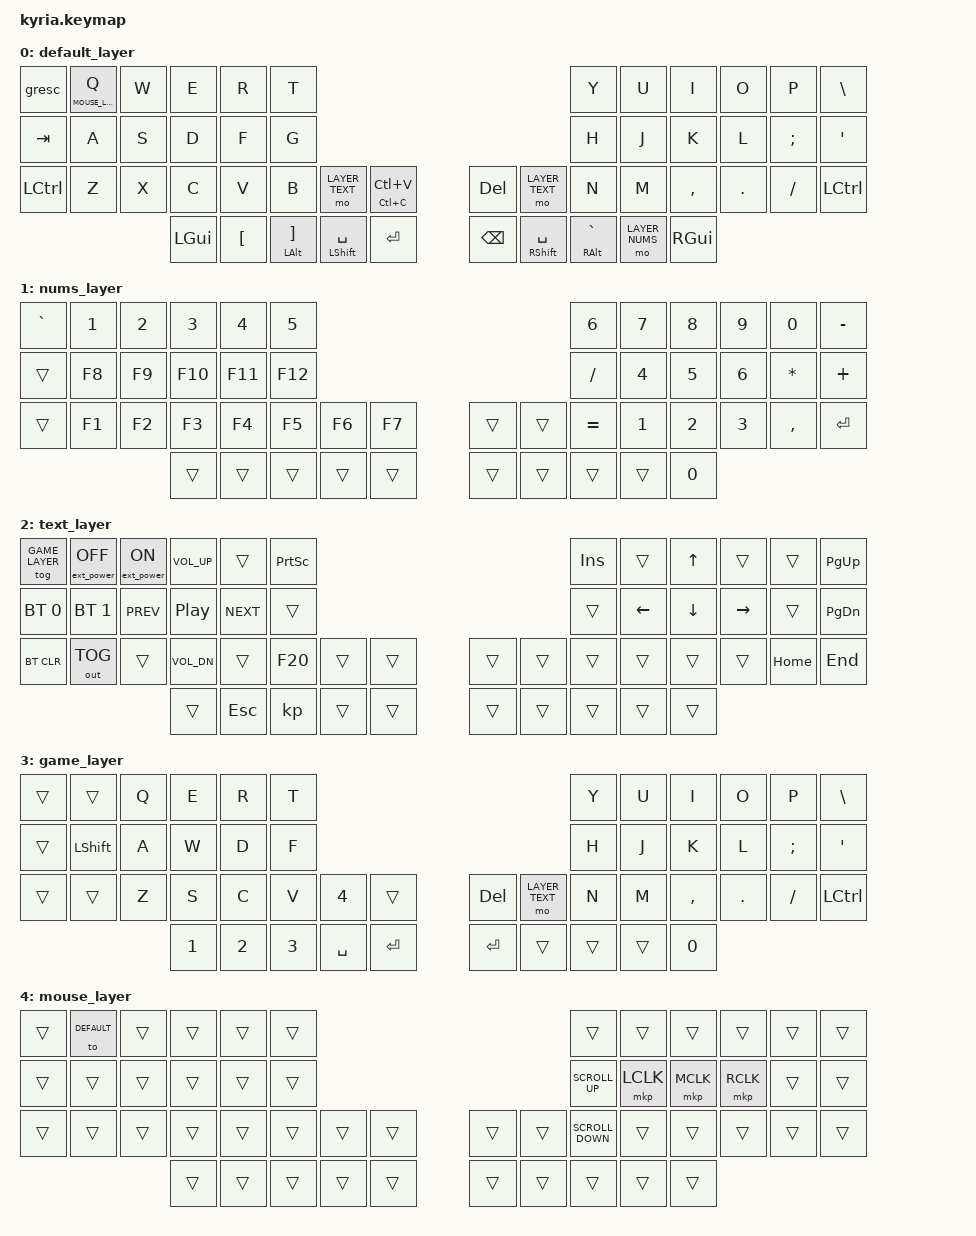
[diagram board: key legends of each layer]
#define DEFAULT 0
// ---------------------------------------------------------------------------------------------------------------------------------
// | ESC  |  Q  |  W  |  E   |  R  |  T    |                                                      |    Y    |   U   |  I    |  O   |   P   |   \  |
// | TAB  |  A  |  S  |  D   |  F  |  G    |                                                      |    H    |   J   |  K    |  L   |   ;   |   '  |
// | CTRL |  Z  |  X  |  C   |  V  |  B    |  *TEXT        |  Copy/Paste  |      |  DEL  |  *TEXT        |    N    |   M   |  ,    |  .   |   /   | CTRL |
//                    | GUI  |  [  | ][alt]|  SPACE [shift]|  RET         |      |  BKSP |  SPACE [shift]|  ` [alt]| *NUMS | R-ALT |

#define LAYER_NUMS 1 
// ---------------------------------------------------------------------------------------------------------------------------------
// |       |   1 |   2 |   3  |   4  |   5  |                                        |  6  |   7   |  8   |  9   |   0   |  -    |
// |       |  F8 |  F9 |  F10 |  F11 |  F12 |                                        |  /  |   4   |  5   |  6   |   *   |  +    |
// |       |  F1 |  F2 |  F3  |  F4  |  F5  |   F6   |  F7   |      |       |        |  =  |   1   |  2   |  3   |   ,   |  RET  |
//                     |      |      |      |        |       |      |       |        |     |       |  0   |

#define LAYER_TEXT 2
// ---------------------------------------------------------------------------------------------------------------------------------
// |       |     |      | V UP    |       |      |                                         |      |       |   ↑   |     |       |  PGUP |
// |       |     | Prev | PLAY    |  Next |      |                                         |      |   ←   |   ↓   |  →  |       |  PGDN |
// |       |     |      | V DOWN  |       |      |       |      |            |      |      |      |       |       |     |  HOME |  END  |
//                      |         |  ESC  |      |       |      |            |      |      |      |       |       |

#define GAME_LAYER 3
// ---------------------------------------------------------------------------------------------------------------------------------
// |       |     |      | V UP    |       |      |                                         | INS  |       |   ↑   |     |       |  PGUP |
// |       |     | Prev | PLAY    |  Next |      |                                         |      |   ←   |   ↓   |  →  |       |  PGDN |
// |       |     |      | V DOWN  |       | F20     |       |      |            |      |      |      |       |       |     |  HOME |  END  |
//                      |         |  ESC  |      |       |      |            |      |      |      |       |       |


#define MOUSE_LAYER 4
// ---------------------------------------------------------------------------------------------------------------------------------
// |       |     |      | V UP    |       |      |                                         |      |       |   ↑   |     |       |  PGUP |
// |       |     | Prev | PLAY    |  Next |      |                                         |      |   ←   |   ↓   |  →  |       |  PGDN |
// |       |     |      | V DOWN  |       |      |       |      |            |      |      |      |       |       |     |  HOME |  END  |
//                      |         |  ESC  |      |       |      |            |      |      |      |       |       |


#include <behaviors.dtsi>
#include <behaviors/mouse_keys.dtsi>
#include <behaviors/mouse_key_press.dtsi>
#include <behaviors/mouse_key_toggle.dtsi>
#include <dt-bindings/zmk/keys.h>
#include <dt-bindings/zmk/bt.h>
#include <dt-bindings/zmk/rgb.h>
#include <dt-bindings/zmk/ext_power.h>
#include <dt-bindings/zmk/outputs.h>
#include <dt-bindings/zmk/mouse.h>

#include <behaviors/insomnia.dtsi>
#include <dt-bindings/zmk/insomnia.h>

#define DEF 0
#define LHB 1
#define NUM 2
#define MSK 3
#define MSC 4

#ifndef MOVE_Y
#define MOVE_Y(n) (0)
#endif
#ifndef MOVE_X
#define MOVE_X(n) (0)
#endif

#define U_MOUSE_MOVE_MAX 1700
#define MOU_U MOVE_Y(-U_MOUSE_MOVE_MAX)
#define MOU_D MOVE_Y(U_MOUSE_MOVE_MAX)
#define MOU_L MOVE_X(-U_MOUSE_MOVE_MAX)
#define MOU_R MOVE_X(U_MOUSE_MOVE_MAX)

#define U_MOUSE_SCROLL_MAX 20
#define SCL_U MOVE_Y(U_MOUSE_SCROLL_MAX)
#define SCL_D MOVE_Y(-U_MOUSE_SCROLL_MAX)
#define SCL_L MOVE_X(-U_MOUSE_SCROLL_MAX)
#define SCL_R MOVE_X(U_MOUSE_SCROLL_MAX)



/ {
  behaviors {
        hm: homerow_mods {
            compatible = "zmk,behavior-hold-tap";
            #binding-cells = <2>;
            tapping_term_ms = <175>;
            flavor = "balanced";
            bindings = <&kp>, <&kp>;
        };
    };
    
        tball1_mmv_ibl {
                compatible = "zmk,input-behavior-listener";
                device = <&tball1>;
                layers = <DEF NUM MSK LHB>;
		evt-type = <INPUT_EV_REL>;
		x-input-code = <INPUT_REL_X>;
		y-input-code = <INPUT_REL_Y>;
                // bindings = <&ib_tog_layer MSK>;
                // bindings = <&ib_fwd_to_hid_io>;
        };
        tball1_msl_ibl {
                compatible = "zmk,input-behavior-listener";
                device = <&tball1>;
                layers = <MSC>;
                evt-type = <INPUT_EV_REL>;
                x-input-code = <INPUT_REL_MISC>;
                y-input-code = <INPUT_REL_WHEEL>;
                y-invert;
                bindings = <&ib_wheel_scaler 1 25>;
        };

        
	
	keymap {
	
		compatible = "zmk,keymap";
	
		default_layer {
			bindings = <
	&gresc  &lt MOUSE_LAYER Q &kp W &kp E &kp R &kp T                                                                &kp Y         &kp U          &kp I    &kp O   &kp P    &kp BSLH
	&kp TAB  &kp A &kp S &kp D &kp F &kp G                                                               &kp H         &kp J          &kp K    &kp L   &kp SEMI &kp SQT
	&kp LCTRL &kp Z &kp X &kp C &kp V &kp B         &mo LAYER_TEXT   &mt LC(C)  LC(V)  &kp DEL  &mo LAYER_TEXT &kp N         &kp M          &kp COMMA &kp DOT &kp FSLH &kp LCTRL 
	               &kp LGUI &kp LBKT &mt LALT RBKT &mt LSHFT SPACE   &kp RET       	 &kp BSPC &mt RSHIFT SPACE   &mt RALT GRAVE &mo LAYER_NUMS &kp RGUI
			>;
		};

		nums_layer {
			bindings = <
	&kp GRAVE &kp N1 &kp N2 &kp N3 &kp N4 &kp N5                                           &kp N6  &kp N7  &kp N8    &kp N9   &kp N0    &kp MINUS  
	&trans   &kp F8    &kp F9    &kp F10   &kp F11   &kp F12                                             &kp SLASH   &kp N4  &kp N5    &kp N6   &kp ASTERISK     &kp PLUS  
	&trans   &kp F1    &kp F2    &kp F3    &kp F4    &kp F5    &kp F6  &kp F7         &trans    &trans   &kp EQUAL    &kp N1  &kp N2    &kp N3   &kp COMMA     &kp RET   
	                   &trans    &trans   &trans    &trans    &trans  				&trans         &trans    &trans   &trans     &kp N0     
			>;
		};
		
		text_layer {
			bindings = <
	&tog GAME_LAYER   &ext_power EP_OFF    &ext_power EP_ON     &kp C_VOL_UP   &trans     &kp PSCRN                                                 &kp INS   &trans    &kp UP   &trans    &trans    &kp PG_UP   
	&bt BT_SEL 0  &bt BT_SEL 1   &kp C_PREV &kp C_PLAY_PAUSE   &kp C_NEXT &trans                                                 &trans  &kp LEFT  &kp DOWN   &kp RIGHT  &trans    &kp PG_DN  
	&bt BT_CLR    &out OUT_TOG    &trans     &kp C_VOL_DN   &trans     &kp F20    &trans    &trans         &trans    &trans    &trans  &trans    &trans     &trans    &kp HOME  &kp END 
	                               &trans       &kp ESC    &kp       &trans    &trans         &trans    &trans    &trans  &trans    &trans     
			>; 
		 };
			
		game_layer {
			bindings = <
	&trans   &trans  &kp Q     &kp E    &kp R   &kp T                                             &kp Y         &kp U          &kp I    &kp O   &kp P    &kp BSLH
	&trans    &kp LSHIFT    &kp A   &kp W    &kp D   &kp F                                               &kp H         &kp J          &kp K    &kp L   &kp SEMI &kp SQT
	&trans   &trans   &kp Z    &kp S    &kp C   &kp V    &kp N4  &trans                &kp DEL  &mo LAYER_TEXT &kp N         &kp M          &kp COMMA &kp DOT &kp FSLH &kp LCTRL   
	                   &kp N1  &kp N2    &kp N3    &kp SPACE    &kp RET  &kp RET          &trans    &trans   &trans     &kp N0     
			>;	
                 
		};
		mouse_layer {
			bindings = <
	&trans   &to DEFAULT  &trans    &trans   &trans    &trans                                         &trans        &trans         &trans    &trans   &trans   &trans
	&trans   &trans    &trans  &trans   &trans  &trans                                       &kp K_SCROLL_UP        &mkp LCLK         &mkp MCLK    &mkp RCLK   &trans &trans
	&trans   &trans   &trans    &trans   &trans  &trans    &trans  &trans               	&trans  &trans &kp K_SCROLL_DOWN    &trans      &trans          &trans &trans &trans  
						&trans &trans   &trans    &trans   &trans               &trans  &trans    &trans   &trans    &trans     
			>;	
					
		};
	};
};
